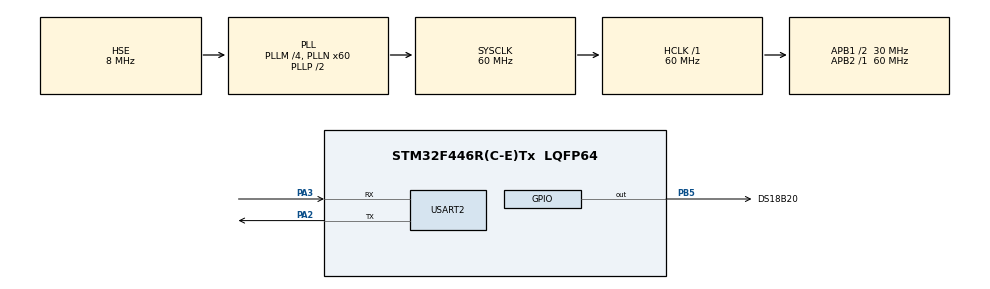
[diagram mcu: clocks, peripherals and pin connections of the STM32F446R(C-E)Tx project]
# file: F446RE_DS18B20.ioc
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Mcu.Family=STM32F4
Mcu.Name=STM32F446R(C-E)Tx
Mcu.Package=LQFP64
NVIC.PriorityGroup=NVIC_PRIORITYGROUP_0
NVIC.TIM6_DAC_IRQn=true\:0\:0\:false\:false\:true\:false\:true\:true
NVIC.TimeBase=TIM6_DAC_IRQn
NVIC.TimeBaseIP=TIM6
PA13.GPIO_Label=TMS
PA13.Mode=Serial_Wire
PA13.Signal=SYS_JTMS-SWDIO
PA14.GPIO_Label=TCK
PA14.Mode=Serial_Wire
PA14.Signal=SYS_JTCK-SWCLK
PA2.Mode=Asynchronous
PA2.Signal=USART2_TX
PA3.Mode=Asynchronous
PA3.Signal=USART2_RX
PB3.GPIO_Label=SWO
PB3.Signal=SYS_JTDO-SWO
PB5.GPIO_Label=DS18B20
PB5.GPIO_ModeDefaultOutputPP=GPIO_MODE_OUTPUT_OD
PB5.GPIO_PuPd=GPIO_NOPULL
PB5.PinState=GPIO_PIN_SET
PB5.Signal=GPIO_Output
PH0-OSC_IN.Mode=HSE-External-Oscillator
PH0-OSC_IN.Signal=RCC_OSC_IN
PH1-OSC_OUT.Mode=HSE-External-Oscillator
PH1-OSC_OUT.Signal=RCC_OSC_OUT
ProjectManager.HeapSize=0x200
ProjectManager.StackSize=0x400
ProjectManager.TargetToolchain=STM32CubeIDE
RCC.48MHZClocksFreq_Value=84000000
RCC.AHBFreq_Value=60000000
RCC.APB1CLKDivider=RCC_HCLK_DIV2
RCC.APB1Freq_Value=30000000
RCC.APB1TimFreq_Value=60000000
RCC.APB2Freq_Value=60000000
RCC.APB2TimFreq_Value=60000000
RCC.CortexFreq_Value=60000000
RCC.FLatency-AdvancedSettings=FLASH_LATENCY_1
RCC.HCLKFreq_Value=60000000
RCC.HSE_VALUE=8000000
RCC.HSI_VALUE=16000000
RCC.PLLM=4
RCC.PLLN=60
RCC.PLLSourceVirtual=RCC_PLLSOURCE_HSE
RCC.SYSCLKFreq_VALUE=60000000
RCC.SYSCLKSource=RCC_SYSCLKSOURCE_PLLCLK
RCC.USBFreq_Value=60000000
RCC.VCOOutputFreq_Value=120000000
TIM7.Prescaler=59
USART2.VirtualMode=VM_ASYNC
VP_SYS_VS_tim6.Mode=TIM6
VP_TIM7_VS_ClockSourceINT.Mode=Enable_Timer
board=NUCLEO-F446RE

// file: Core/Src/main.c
/* USER CODE BEGIN Header */
/**
  ******************************************************************************
  * @file           : main.c
  * @brief          : Main program body
  ******************************************************************************
  * @attention
  *
  * Copyright (c) 2023 STMicroelectronics.
  * All rights reserved.
  *
  * This software is licensed under terms that can be found in the LICENSE file
  * in the root directory of this software component.
  * If no LICENSE file comes with this software, it is provided AS-IS.
  *
  ******************************************************************************
  */
/* USER CODE END Header */
#include "main.h"

/* USER CODE BEGIN Includes */
#include "ds18b20.h"
#include <stdio.h>
/* USER CODE END Includes */

TIM_HandleTypeDef htim7;

UART_HandleTypeDef huart2;

/* USER CODE BEGIN PV */
float temp;
HAL_StatusTypeDef status;

// PARTI
//uint8_t ds1[DS18B20_ROM_CODE_SIZE];

// PART II
const uint8_t ds1[] = {0x28, 0x26, 0xc3, 0x57, 0x4, 0xe1, 0x3c, 0x1a};
const uint8_t ds2[] = {0x28, 0xf2, 0xa, 0x49, 0xf6, 0xf1, 0x3c, 0xd0};
uint8_t my_scratchpad_before[DS18B20_SCRATCHPAD_SIZE];
uint8_t my_scratchpad_after[DS18B20_SCRATCHPAD_SIZE];
/* USER CODE END PV */

void SystemClock_Config(void);
static void MX_GPIO_Init(void);
static void MX_TIM7_Init(void);
static void MX_USART2_UART_Init(void);
/* USER CODE BEGIN PFP */

// bit-banging
void delay_us(uint32_t us);
HAL_StatusTypeDef wire_reset(void);

void write_bit(int value);
int read_bit(void);

void wire_write(uint8_t byte);
uint8_t wire_read(void);

// CRC
uint8_t byte_crc(uint8_t crc, uint8_t byte);
uint8_t wire_crc (const uint8_t * data, int len);
/* USER CODE END PFP */

int main(void)
{

  /* MCU Configuration--------------------------------------------------------*/

  /* Reset of all peripherals, Initializes the Flash interface and the Systick. */
  HAL_Init();

  /* Configure the system clock */
  SystemClock_Config();

  /* Initialize all configured peripherals */
  MX_GPIO_Init();
  MX_TIM7_Init();
  MX_USART2_UART_Init();
  /* USER CODE BEGIN 2 */
  if ( HAL_OK != ds18b20_init() )
  {
	  Error_Handler();
  }

  // PART I
//  if ( HAL_OK != ds18b20_read_address(ds1) )
//  {
//	  Error_Handler();
//  }

  // PART III
//  if ( HAL_OK != ds18b20_read_scratchpad(NULL, my_scratchpad_before) )
//  {
//	  Error_Handler();
//  }
//
//
//  if ( HAL_OK != ds18b20_write_scratchpad(NULL, 12) )
//  {
//	  Error_Handler();
//  }
//  if ( HAL_OK != ds18b20_read_scratchpad(NULL, my_scratchpad_after) )
//  {
//	  Error_Handler();
//  }

  /* USER CODE END 2 */

  /* Infinite loop */
  /* USER CODE BEGIN WHILE */
  while (1)
  {
	  // PART I
//	  ds18b20_start_measure(NULL);
//	  HAL_Delay(750);
//
//	  temp = ds18b20_get_temp(NULL);
//	  if (80.0f <= temp )
//	  {
//		  printf("Sensor error...\n");
//		  status = HAL_ERROR;
//	  }
//	  else
//	  {
//		  printf("T1 = %.1f*C\n", temp);
//		  status = HAL_OK;
//	  }

	  // PART II
	  ds18b20_start_measure(ds1);
	  ds18b20_start_measure(ds2);
	  HAL_Delay(750);

	  temp = ds18b20_get_temp(ds1);
	  if (80.0f <= temp )
	  {
		  printf("Sensor error...\n");
		  status = HAL_ERROR;
	  }
	  else
	  {
		  printf("T1 = %.1f*C\n", temp);
		  status = HAL_OK;
	  }

	  temp = ds18b20_get_temp(ds2);
	  if (80.0f <= temp )
	  {
		  printf("Sensor error...\n");
		  status = HAL_ERROR;
	  }
	  else
	  {
		  printf("T2 = %.1f*C\n", temp);
		  status = HAL_OK;
	  }

	  // PART III
//	  ds18b20_start_measure(NULL);
//	  HAL_Delay(200);
//
//	  temp = ds18b20_get_temp(NULL);
//	  if (80.0f <= temp )
//	  {
//		  printf("Sensor error...\n");
//		  status = HAL_ERROR;
//	  }
//	  else
//	  {
//		  printf("T1 = %.1f*C\n", temp);
//		  status = HAL_OK;
//	  }
    /* USER CODE END WHILE */

  }
}

void SystemClock_Config(void)
{
  RCC_OscInitTypeDef RCC_OscInitStruct = {0};
  RCC_ClkInitTypeDef RCC_ClkInitStruct = {0};

  /** Configure the main internal regulator output voltage
  */
  __HAL_RCC_PWR_CLK_ENABLE();
  __HAL_PWR_VOLTAGESCALING_CONFIG(PWR_REGULATOR_VOLTAGE_SCALE3);

  /** Initializes the RCC Oscillators according to the specified parameters
  * in the RCC_OscInitTypeDef structure.
  */
  RCC_OscInitStruct.OscillatorType = RCC_OSCILLATORTYPE_HSE;
  RCC_OscInitStruct.HSEState = RCC_HSE_ON;
  RCC_OscInitStruct.PLL.PLLState = RCC_PLL_ON;
  RCC_OscInitStruct.PLL.PLLSource = RCC_PLLSOURCE_HSE;
  RCC_OscInitStruct.PLL.PLLM = 4;
  RCC_OscInitStruct.PLL.PLLN = 60;
  RCC_OscInitStruct.PLL.PLLP = RCC_PLLP_DIV2;
  RCC_OscInitStruct.PLL.PLLQ = 2;
  RCC_OscInitStruct.PLL.PLLR = 2;
  if (HAL_RCC_OscConfig(&RCC_OscInitStruct) != HAL_OK)
  {
    Error_Handler();
  }

  /** Initializes the CPU, AHB and APB buses clocks
  */
  RCC_ClkInitStruct.ClockType = RCC_CLOCKTYPE_HCLK|RCC_CLOCKTYPE_SYSCLK
                              |RCC_CLOCKTYPE_PCLK1|RCC_CLOCKTYPE_PCLK2;
  RCC_ClkInitStruct.SYSCLKSource = RCC_SYSCLKSOURCE_PLLCLK;
  RCC_ClkInitStruct.AHBCLKDivider = RCC_SYSCLK_DIV1;
  RCC_ClkInitStruct.APB1CLKDivider = RCC_HCLK_DIV2;
  RCC_ClkInitStruct.APB2CLKDivider = RCC_HCLK_DIV1;

  if (HAL_RCC_ClockConfig(&RCC_ClkInitStruct, FLASH_LATENCY_1) != HAL_OK)
  {
    Error_Handler();
  }
}

static void MX_TIM7_Init(void)
{

  TIM_MasterConfigTypeDef sMasterConfig = {0};

  htim7.Instance = TIM7;
  htim7.Init.Prescaler = 59;
  htim7.Init.CounterMode = TIM_COUNTERMODE_UP;
  htim7.Init.Period = 65535;
  htim7.Init.AutoReloadPreload = TIM_AUTORELOAD_PRELOAD_DISABLE;
  if (HAL_TIM_Base_Init(&htim7) != HAL_OK)
  {
    Error_Handler();
  }
  sMasterConfig.MasterOutputTrigger = TIM_TRGO_RESET;
  sMasterConfig.MasterSlaveMode = TIM_MASTERSLAVEMODE_DISABLE;
  if (HAL_TIMEx_MasterConfigSynchronization(&htim7, &sMasterConfig) != HAL_OK)
  {
    Error_Handler();
  }

}

static void MX_USART2_UART_Init(void)
{

  huart2.Instance = USART2;
  huart2.Init.BaudRate = 115200;
  huart2.Init.WordLength = UART_WORDLENGTH_8B;
  huart2.Init.StopBits = UART_STOPBITS_1;
  huart2.Init.Parity = UART_PARITY_NONE;
  huart2.Init.Mode = UART_MODE_TX_RX;
  huart2.Init.HwFlowCtl = UART_HWCONTROL_NONE;
  huart2.Init.OverSampling = UART_OVERSAMPLING_16;
  if (HAL_UART_Init(&huart2) != HAL_OK)
  {
    Error_Handler();
  }

}

static void MX_GPIO_Init(void)
{
  GPIO_InitTypeDef GPIO_InitStruct = {0};

  /* GPIO Ports Clock Enable */
  __HAL_RCC_GPIOH_CLK_ENABLE();
  __HAL_RCC_GPIOA_CLK_ENABLE();
  __HAL_RCC_GPIOB_CLK_ENABLE();

  /*Configure GPIO pin Output Level */
  HAL_GPIO_WritePin(DS18B20_GPIO_Port, DS18B20_Pin, GPIO_PIN_SET);

  /*Configure GPIO pin : DS18B20_Pin */
  GPIO_InitStruct.Pin = DS18B20_Pin;
  GPIO_InitStruct.Mode = GPIO_MODE_OUTPUT_OD;
  GPIO_InitStruct.Pull = GPIO_NOPULL;
  GPIO_InitStruct.Speed = GPIO_SPEED_FREQ_LOW;
  HAL_GPIO_Init(DS18B20_GPIO_Port, &GPIO_InitStruct);

}

/* USER CODE BEGIN 4 */
int __io_putchar(int ch)
{
  if (ch == '\n') {
    __io_putchar('\r');
  }

  HAL_UART_Transmit(&huart2, (uint8_t*)&ch, 1, HAL_MAX_DELAY);

  return 1;
}
/* USER CODE END 4 */

void HAL_TIM_PeriodElapsedCallback(TIM_HandleTypeDef *htim)
{
  if (htim->Instance == TIM6) {
    HAL_IncTick();
  }
}

void Error_Handler(void)
{
  __disable_irq();
  while (1)
  {
  }
}
